# PIC32MZ2064DAL176 device description
Architecture: MIPS; Family: PIC32MZDA; Series: PIC32MZ
Registers are 32-bit, read-write, no defined reset value unless marked. A register's access mark holds for its fields unless they carry their own. Offsets are from the block's base; [hi:lo] are bit positions; {n}, {i} and the like mark numbered series; 'fields as' and 'values as' point back to an identical list.

## CMP
Instances: CMP 0x1f84c000 in periph_pb3_std
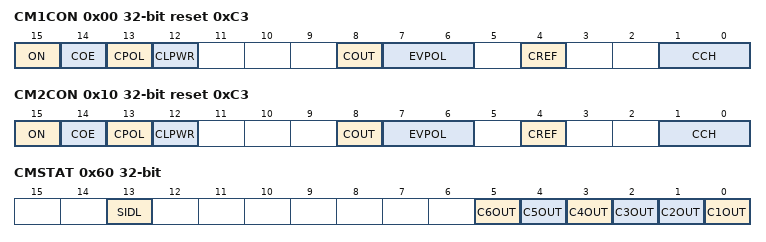
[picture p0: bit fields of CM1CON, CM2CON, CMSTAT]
0x00 CM1CON reset 0xC3 — Comparator Control Register
  [15] ON — Comparator ON bit
    1=Module is enabled. Setting this bit does not affect the other bits in this register; 0=Module is disabled and does not consume current. Clearing this bit does not affect the other bits in this register
  [14] COE — Comparator Output Enable bit
    1=Comparator output is driven on the output CxOUT pin; 0=Comparator output is not driven on the output CxOUT pin
  [13] CPOL — Comparator Output Inversion bit
    1=Output is inverted; 0=Output is not inverted
  [12] CLPWR
  [8] COUT — Comparator Output bit
    1=Output of the Comparator is a 1; 0=Output of the Comparator is a 0
  [7:6] EVPOL — Interrupt Event Polarity Select bits
    3=Comparator interrupt is generated on a low-to-high or high-to-low transition of the comparator output; 2=Comparator interrupt is generated on a high-to-low transition of the comparator output; 1=Comparator interrupt is generated on a low-to-high transition of the comparator output; 0=Comparator interrupt generation is disabled
  [4] CREF — Comparator Positive Input Configure bit
    1=Comparator non-inverting input is connected to the internal CVref; 0=Comparator non-inverting input is connected to the CxINA pin
  [1:0] CCH — Comparator Negative Input Select bits for Comparator
    3=Comparator inverting input is connected to the IVREF; 2=Comparator inverting input is connected to the CxIND pin; 1=Comparator inverting input is connected to the CxINC pin; 0=Comparator inverting input is connected to the CxINB pin
0x10 CM2CON reset 0xC3 — Comparator Control Register
  fields as CM1CON
0x60 CMSTAT — Comparator Status Register
  [13] SIDL — Stop in Idle Control bit
    1=All Comparator modules are disabled in Idle mode; 0=All Comparator modules continue to operate in the Idle mode
  [n-1] C{n}OUT (n=3..6)
  [1] C2OUT — Comparator Output bit
    1=Output of Comparator 2 is a 1; 0=Output of Comparator 2 is a 0
  [0] C1OUT — Comparator Output bit
    1=Output of Comparator 1 is a 1; 0=Output of Comparator 1 is a 0

## RCON
Instances: RCON 0x1f801200 in periph_pb1_std
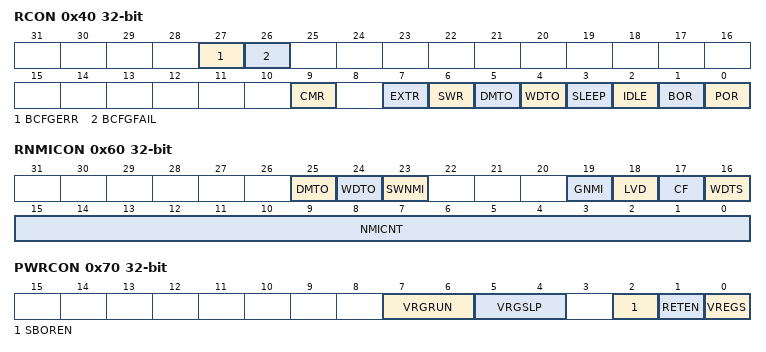
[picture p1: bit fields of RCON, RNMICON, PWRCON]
0x40 RCON — Reset Control Register
  [27] BCFGERR — Primary Configuration Registers Error Flag bit
    1=An error occurred during a read of the primary configuration registers; 0=No error occurred during a read of the primary configuration registers
  [26] BCFGFAIL — Primary/Secondary Configuration Registers Error Flag bit
    1=An error occurred during a read of the primary and alternate configuration registers; 0=No error occurred during a read of the primary and alternate configuration registers
  [9] CMR — Configuration Mismatch Reset Flag bit
    1=A Configuration Mismatch Reset has occurred; 0=A Configuration Mismatch Reset has not occurred
  [7] EXTR — External Reset (MCLR) Pin Flag bit
    1=Master Clear (pin) Reset has occurred; 0=Master Clear (pin) Reset has not occurred
  [6] SWR — Software Reset Flag bit
    1=Software Reset was executed; 0=Software Reset was not executed
  [5] DMTO — Deadman Timer Time-out Flag bit
    1=A DMT time-out has occurred; 0=A DMT time-out has not occurred
  [4] WDTO — Watchdog Timer Time-out Flag bit
    1=WDT Time-out has occurred; 0=WDT Time-out has not occurred
  [3] SLEEP — Wake From Sleep Flag bit
    1=Device was in Sleep mode; 0=Device was not in Sleep mode
  [2] IDLE — Wake From Idle Flag bit
    1=Device was in Idle mode; 0=Device was not in Idle mode
  [1] BOR — Brown-out Reset Flag bit
    1=Brown-out Reset has occurred; 0=Brown-out Reset has not occurred
  [0] POR — Power-on Reset Flag bit
    1=Power-on Reset has occurred; 0=Power-on Reset has not occurred
0x50 RSWRST wo — Software Reset Register
  [0] SWRST — Software Reset Trigger bit
    1=Enable software Reset event; 0=No effect
0x60 RNMICON — Non-maskable Interrupt (NMI) Control Register
  [25] DMTO — Deadman Timer Time-out Flag bit
    1=DMT time-out has occurred and caused a NMI; 0=DMT time-out has not occurred
  [24] WDTO — Watchdog Timer Time-Out Flag bit
    1=WDT time-out has occurred and caused a NMI; 0=WDT time-out has not occurred
  [23] SWNMI — Software NMI Trigger
    1=An NMI will be generated; 0=An NMI will not be generated
  [19] GNMI — General NMI bit
    1=A general NMI event has been detected or a user-initiated NMI event has occurred; 0=A general NMI event has not been detected
  [18] LVD
  [17] CF — Clock Fail Detect bit
    1=FSCM has detected clock failure and caused an NMI; 0=FSCM has not detected clock failure
  [16] WDTS — Watchdog Timer Time-out in Sleep Mode Flag bit
    1=WDT time-out has occurred during Sleep mode and caused a wake-up from sleep; 0=WDT time-out has not occurred during Sleep mode
  [15:0] NMICNT — NMI Reset Counter Value bits
    0xffff=65535 SYSCLK cycles before a device Reset occurs; 1=1 SYSCLK cycle before a device Reset occurs; 0=No delay between NMI assertion and device Reset event
0x70 PWRCON — Power Control Register
  [7:6] VRGRUN
  [5:4] VRGSLP
  [2] SBOREN
  [1] RETEN
  [0] VREGS — Voltage Regulator Stand-by Enable bit
    1=Voltage regulator will remain active during Sleep; 0=Voltage regulator will go to Stand-by mode during Sleep

## Notices in the file
Copyright (c) 2017 Microchip Technology Inc.
SPDX-License-Identifier: Apache-2.0
Licensed under the Apache License, Version 2.0 (the "License");
you may not use this file except in compliance with the License.
You may obtain a copy of the License at
http://www.apache.org/licenses/LICENSE-2.0
Unless required by applicable law or agreed to in writing, software
distributed under the License is distributed on an "AS IS" BASIS,
WITHOUT WARRANTIES OR CONDITIONS OF ANY KIND, either express or implied.
See the License for the specific language governing permissions and
limitations under the License.
